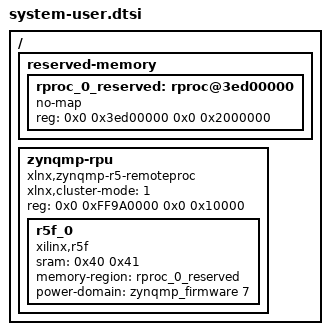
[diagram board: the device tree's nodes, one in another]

/ {
reserved-memory {
    #address-cells = <2>;
    #size-cells = <2>;
    ranges;
    rproc_0_reserved: rproc@3ed00000 {
        no-map;
        reg = <0x0 0x3ed00000 0x0 0x2000000>;
    };
};
zynqmp-rpu {
    compatible = "xlnx,zynqmp-r5-remoteproc";
    xlnx,cluster-mode = <1>;
    ranges;
    reg = <0x0 0xFF9A0000 0x0 0x10000>;
    #address-cells = <0x2>;
    #size-cells = <0x2>;
    r5f_0 {
        compatible = "xilinx,r5f";
        #address-cells = <2>;
        #size-cells = <2>;
        ranges;
        sram = <0x40 0x41>;
        memory-region = <&rproc_0_reserved>;
        power-domain = <&zynqmp_firmware 7>;
    };
};
};
